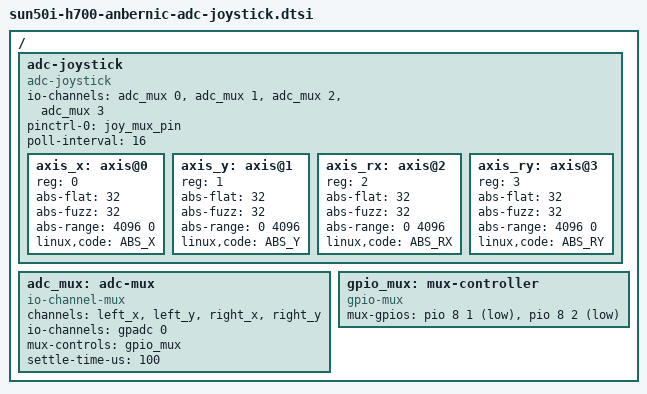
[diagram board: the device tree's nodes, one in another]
// SPDX-License-Identifier: (GPL-2.0-only OR BSD-2-Clause)
#include <dt-bindings/input/linux-event-codes.h>

/ {
	adc-joystick {
		compatible = "adc-joystick";
		io-channels = <&adc_mux 0>, <&adc_mux 1>,
			      <&adc_mux 2>, <&adc_mux 3>;
		pinctrl-0 = <&joy_mux_pin>;
		pinctrl-names = "default";
		poll-interval = <16>; /* a frame: games read it every frame */
		#address-cells = <1>;
		#size-cells = <0>;

		axis_x: axis@0 {
			reg = <0>;
			abs-flat = <32>;
			abs-fuzz = <32>;
			abs-range = <4096 0>;
			linux,code = <ABS_X>;
		};

		axis_y: axis@1 {
			reg = <1>;
			abs-flat = <32>;
			abs-fuzz = <32>;
			abs-range = <0 4096>;
			linux,code = <ABS_Y>;
		};

		axis_rx: axis@2 {
			reg = <2>;
			abs-flat = <32>;
			abs-fuzz = <32>;
			abs-range = <0 4096>;
			linux,code = <ABS_RX>;
		};

		axis_ry: axis@3 {
			reg = <3>;
			abs-flat = <32>;
			abs-fuzz = <32>;
			abs-range = <4096 0>;
			linux,code = <ABS_RY>;
		};
	};

	adc_mux: adc-mux {
		compatible = "io-channel-mux";
		channels = "left_x", "left_y", "right_x", "right_y";
		#io-channel-cells = <1>;
		io-channels = <&gpadc 0>;
		io-channel-names = "parent";
		mux-controls = <&gpio_mux>;
		settle-time-us = <100>;
	};

	gpio_mux: mux-controller {
		compatible = "gpio-mux";
		mux-gpios = <&pio 8 1 GPIO_ACTIVE_LOW>,
			    <&pio 8 2 GPIO_ACTIVE_LOW>;
		#mux-control-cells = <0>;
	};
};
